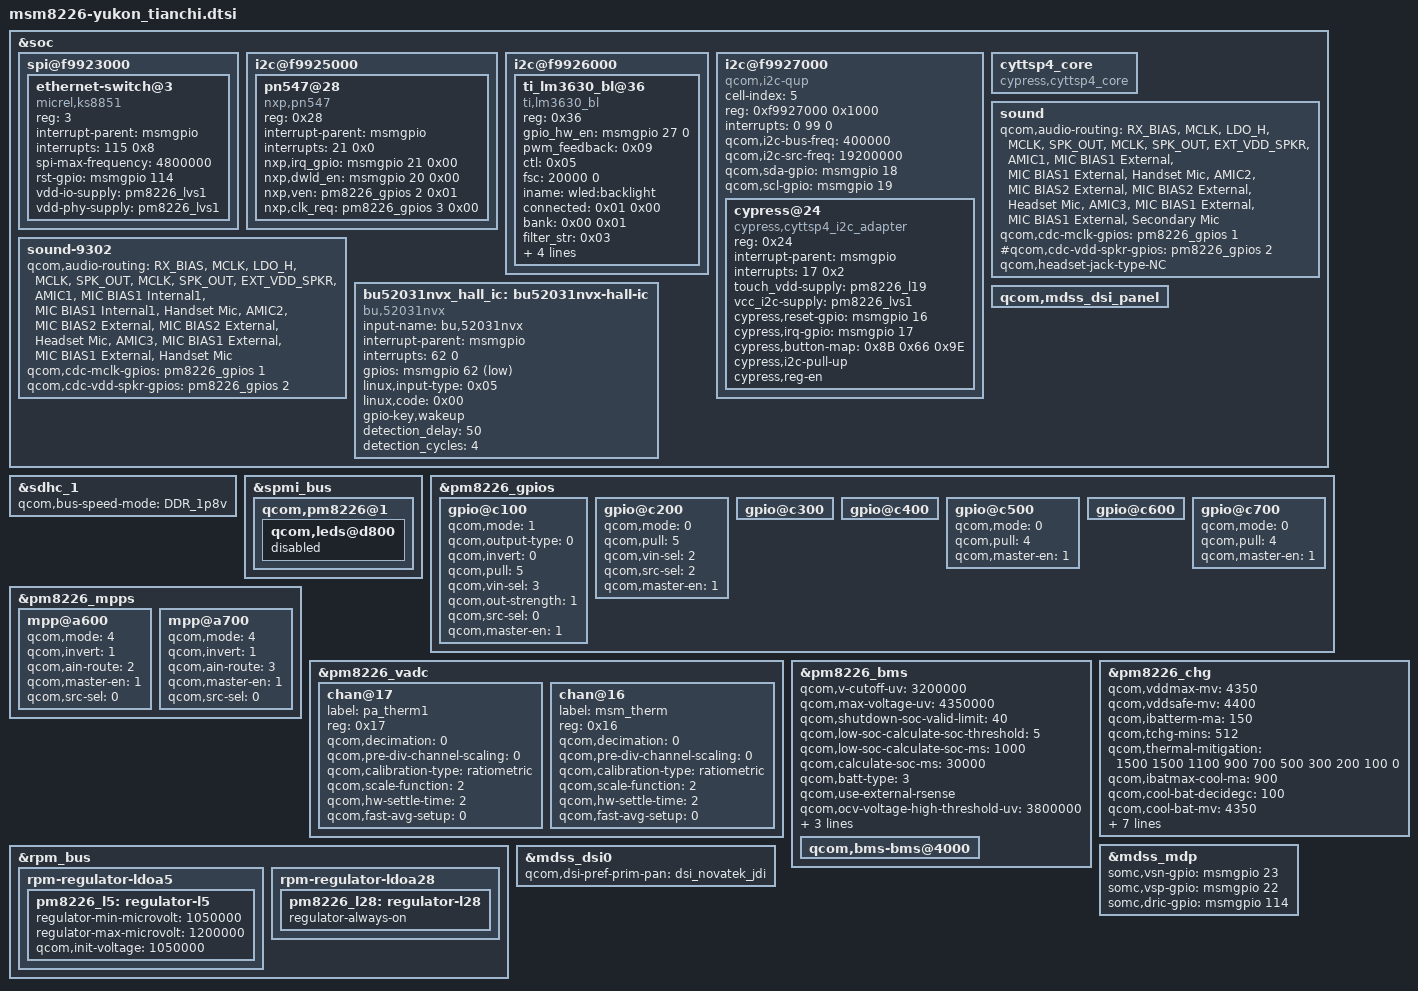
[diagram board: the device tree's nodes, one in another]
/* Copyright (c) 2013, The Linux Foundation. All rights reserved.
 * Copyright (C) 2014 Sony Mobile Communications AB.
 *
 * This program is free software; you can redistribute it and/or modify
 * it under the terms of the GNU General Public License version 2 and
 * only version 2 as published by the Free Software Foundation.
 *
 * This program is distributed in the hope that it will be useful,
 * but WITHOUT ANY WARRANTY; without even the implied warranty of
 * MERCHANTABILITY or FITNESS FOR A PARTICULAR PURPOSE.  See the
 * GNU General Public License for more details.
 *
 * NOTE: This file has been modified by Sony Mobile Communications AB.
 * Modifications are licensed under the License.
 */

#include "msm8226-yukon_common.dtsi"
#include "dsi-panel-tianchi.dtsi"
#include "msm8226-yukon_tianchi-camera-sensor.dtsi"

&soc {

	spi@f9923000 {
		ethernet-switch@3 {
			compatible = "micrel,ks8851";
			reg = <3>;
			interrupt-parent = <&msmgpio>;
			interrupts = <115 0x8>;
			spi-max-frequency = <4800000>;
			rst-gpio = <&msmgpio 114 0>;
			vdd-io-supply = <&pm8226_lvs1>;
			vdd-phy-supply = <&pm8226_lvs1>;
		};
	};

	i2c@f9925000 { /* BLSP-1 QUP-3 */
		pn547@28 {
			compatible = "nxp,pn547";
			reg = <0x28>;
			interrupt-parent = <&msmgpio>;
			interrupts = <21 0x0>;
			nxp,irq_gpio = <&msmgpio 21 0x00>;
			nxp,dwld_en = <&msmgpio 20 0x00>;
			nxp,ven = <&pm8226_gpios 2 0x01>;
			nxp,clk_req = <&pm8226_gpios 3 0x00>;
		};
	};

	i2c@f9926000 { /* BLSP-1 QUP-4 */
		ti_lm3630_bl@36 {
			compatible = "ti,lm3630_bl";
			reg = <0x36>;
			gpio_hw_en = <&msmgpio 27 0>;
			pwm_feedback = <0x09>;
			ctl = <0x05>;
			fsc = <20000 0>;
			iname = "wled:backlight";
			connected = <0x01 0x00>;
			bank = <0x00 0x01>;
			filter_str = <0x03>;
			ovp_boost = <0x46>;
			led_fault = <0x00>;
			intf_name = "wled:backlight";
			brightness = <255 0>;
		};
	};

	i2c@f9927000 { /* BLSP1 QUP5 */
		cell-index = <5>;
		compatible = "qcom,i2c-qup";
		#address-cells = <1>;
		#size-cells = <0>;
		reg-names = "qup_phys_addr";
		reg = <0xf9927000 0x1000>;
		interrupt-names = "qup_err_intr";
		interrupts = <0 99 0>;
		qcom,i2c-bus-freq = <400000>;
		qcom,i2c-src-freq = <19200000>;
		qcom,sda-gpio = <&msmgpio 18 0>;
		qcom,scl-gpio = <&msmgpio 19 0>;
		cypress@24 {
			compatible = "cypress,cyttsp4_i2c_adapter";
			reg = <0x24>;
			interrupt-parent = <&msmgpio>;
			interrupts = <17 0x2>;
			touch_vdd-supply = <&pm8226_l19>;
                        vcc_i2c-supply = <&pm8226_lvs1>;
			cypress,reset-gpio = <&msmgpio 16 0x00>;
			cypress,irq-gpio = <&msmgpio 17 0x00>;
			cypress,button-map = <0x8B 0x66 0x9E>;
			cypress,i2c-pull-up;
			cypress,reg-en;
		};

	};
	cyttsp4_core {
		compatible = "cypress,cyttsp4_core";
	};

	sound {
		qcom,audio-routing =
			"RX_BIAS", "MCLK",
			"LDO_H", "MCLK",
			"SPK_OUT", "MCLK",
			"SPK_OUT", "EXT_VDD_SPKR",
			"AMIC1", "MIC BIAS1 External",
			"MIC BIAS1 External", "Handset Mic",
			"AMIC2", "MIC BIAS2 External",
			"MIC BIAS2 External", "Headset Mic",
			"AMIC3", "MIC BIAS1 External",
			"MIC BIAS1 External", "Secondary Mic";

		qcom,cdc-mclk-gpios = <&pm8226_gpios 1 0>;
		#qcom,cdc-vdd-spkr-gpios = <&pm8226_gpios 2 0>;
		qcom,headset-jack-type-NC;
	};

	sound-9302 {
		qcom,audio-routing =
			"RX_BIAS", "MCLK",
			"LDO_H", "MCLK",
			"SPK_OUT", "MCLK",
			"SPK_OUT", "EXT_VDD_SPKR",
			"AMIC1", "MIC BIAS1 Internal1",
			"MIC BIAS1 Internal1", "Handset Mic",
			"AMIC2", "MIC BIAS2 External",
			"MIC BIAS2 External", "Headset Mic",
			"AMIC3", "MIC BIAS1 External",
			"MIC BIAS1 External", "Handset Mic";

		qcom,cdc-mclk-gpios = <&pm8226_gpios 1 0>;
		qcom,cdc-vdd-spkr-gpios = <&pm8226_gpios 2 0>;
	};

	bu52031nvx_hall_ic: bu52031nvx-hall-ic {
		compatible = "bu,52031nvx";
		input-name = "bu,52031nvx";
		interrupt-parent = <&msmgpio>;
		interrupts = <62 0>;
		gpios = <&msmgpio 62 0x1>;
		linux,input-type = <0x05>;
		linux,code = <0x00>;
		gpio-key,wakeup;
		detection_delay = <50>;
		detection_cycles = <4>;
	};

        qcom,mdss_dsi_panel {
                status = "ok";
        };

};

&sdhc_1 {
	qcom,bus-speed-mode = "DDR_1p8v";
};

&spmi_bus {
	qcom,pm8226@1 {
		qcom,leds@d800 {
			status = "disabled";
		};
	};
};

&pm8226_gpios {
	/* GPIO_2: NFC_EN*/
	gpio@c100 {
		qcom,mode = <1>; /* QPNP_PIN_MODE_DIG_OUT */
		qcom,output-type = <0>; /* QPNP_PIN_OUT_BUF_CMOS */
		qcom,invert = <0>; /* QPNP_PIN_INVERT_DISABLE */
		qcom,pull = <5>; /* QPNP_PIN_PULL_NO */
		qcom,vin-sel = <3>; /* QPNP_PIN_VIN3 = VREG_L6 */
		qcom,out-strength = <1>; /* QPNP_PIN_OUT_STRENGTH_LOW */
		qcom,src-sel = <0>; /* QPNP_PIN_SEL_FUNC_CONSTANT */
		qcom,master-en = <1>; /* enable this gpio */
	};

	/* GPIO_3: NFC_CLK_REQ*/
	gpio@c200 {
		qcom,mode = <0>;		/* QPNP_PIN_MODE_DIG_IN */
		qcom,pull = <5>;		/* QPNP_PIN_PULL_NO */
		qcom,vin-sel = <2>;		/* QPNP_PIN_VIN2 */
		qcom,src-sel = <2>;		/* QPNP_PIN_SEL_FUNC_1 */
		qcom,master-en = <1>;
	};

	/* GPIO_4: BATT_UIM_ALARM*/
	/* Follow QCT */
	gpio@c300 {
	};

	/* GPIO_5: FLASH_STROBE_TRIG*/
	/* Follow QCT */
	gpio@c400 {
	};

	/* GPIO_6: NC*/
	gpio@c500 {
		qcom,mode = <0>;		/* QPNP_PIN_MODE_DIG_IN */
		qcom,pull = <4>;		/* QPNP_PIN_PULL_DN */
		qcom,master-en = <1>;
	};

	/* GPIO_7: TX_GTR_THRESH*/
	/* Follow QCT */
	gpio@c600 {
	};

	/* GPIO_8: NC*/
	gpio@c700 {
		qcom,mode = <0>;		/* QPNP_PIN_MODE_DIG_IN */
		qcom,pull = <4>;		/* QPNP_PIN_PULL_DN */
		qcom,master-en = <1>;
	};
};

&pm8226_mpps {
	mpp@a600 {
		/* MSM_THERM config */
		qcom,mode = <4>; /* AIN input */
		qcom,invert = <1>; /* Enable MPP */
		qcom,ain-route = <2>; /* AMUX 7 */
		qcom,master-en = <1>;
		qcom,src-sel = <0>; /* Function constant */
	};

	mpp@a700 {
		/* PA_THERM1 config */
		qcom,mode = <4>; /* AIN input */
		qcom,invert = <1>; /* Enable MPP */
		qcom,ain-route = <3>; /* AMUX 8 */
		qcom,master-en = <1>;
		qcom,src-sel = <0>; /* Function constant */
	};
};

&pm8226_vadc {
	chan@17 {
		label = "pa_therm1";
		reg = <0x17>;
		qcom,decimation = <0>;
		qcom,pre-div-channel-scaling = <0>;
		qcom,calibration-type = "ratiometric";
		qcom,scale-function = <2>;
		qcom,hw-settle-time = <2>;
		qcom,fast-avg-setup = <0>;
	};

	chan@16 {
		label = "msm_therm";
		reg = <0x16>;
		qcom,decimation = <0>;
		qcom,pre-div-channel-scaling = <0>;
		qcom,calibration-type = "ratiometric";
		qcom,scale-function = <2>;
		qcom,hw-settle-time = <2>;
		qcom,fast-avg-setup = <0>;
	};
};

&pm8226_bms {
	status = "ok";

	qcom,v-cutoff-uv = <3200000>;
	qcom,max-voltage-uv = <4350000>;
	qcom,shutdown-soc-valid-limit = <40>;
	qcom,low-soc-calculate-soc-threshold = <5>;
	qcom,low-soc-calculate-soc-ms = <1000>;
	qcom,calculate-soc-ms = <30000>;
	qcom,batt-type = <3>;
	qcom,use-external-rsense;
	qcom,ocv-voltage-high-threshold-uv = <3800000>;
	qcom,ocv-voltage-low-threshold-uv = <3750000>;
	qcom,clamp-soc-max-count = <2>;
	qcom,chg-term-ua = <150000>;

	qcom,bms-bms@4000 {
		status = "ok";
	};
};

&pm8226_chg {
	qcom,vddmax-mv = <4350>;
	qcom,vddsafe-mv = <4400>;
	qcom,ibatterm-ma = <150>;
	qcom,tchg-mins = <512>;
	qcom,thermal-mitigation = <1500 1500 1100 900 700 500 300 200 100 0>;
	qcom,ibatmax-cool-ma = <900>;
	qcom,cool-bat-decidegc = <100>;
	qcom,cool-bat-mv = <4350>;
	qcom,ibatmax-warm-ma = <900>;
	qcom,warm-bat-decidegc = <450>;
	qcom,warm-bat-mv = <4200>;
	qcom,vbatdet-delta-mv = <20>;
	qcom,vbatdet-delta-soc = <1>;
	qcom,ibatmax-cool-ma = <900>;
	qcom,batt-hot-percentage = <25>;
	qcom,duty-cycle-100p;
};

&rpm_bus {
	rpm-regulator-ldoa5 {
		pm8226_l5: regulator-l5 {
			regulator-min-microvolt = <1050000>;
			regulator-max-microvolt = <1200000>;
			qcom,init-voltage = <1050000>;
		};
	};
	rpm-regulator-ldoa28 {
		pm8226_l28: regulator-l28 {
			regulator-always-on;
		};
	};
};

&bu52031nvx_hall_ic {
        status = "ok";
};

&mdss_mdp {
	somc,vsn-gpio = <&msmgpio 23 0>;
	somc,vsp-gpio = <&msmgpio 22 0>;
	somc,dric-gpio = <&msmgpio 114 0>;
};

&mdss_dsi0 {
	qcom,dsi-pref-prim-pan = <&dsi_novatek_jdi>;
};
